# AT32A423xx_v2 register map
Vendor: Keil; Series: AT32A423; File version: 1.0
CPU: CM4 r0p1, little endian, no MPU, FPU, 4 interrupt priority bits
Registers are 32-bit, read-write, reset 0x0 unless marked. A register's access mark holds for its fields unless they carry their own. Offsets are from the block's base; [hi:lo] are bit positions; {n}, {i} and the like mark numbered series.

## EXINT
Base 0x40013C00
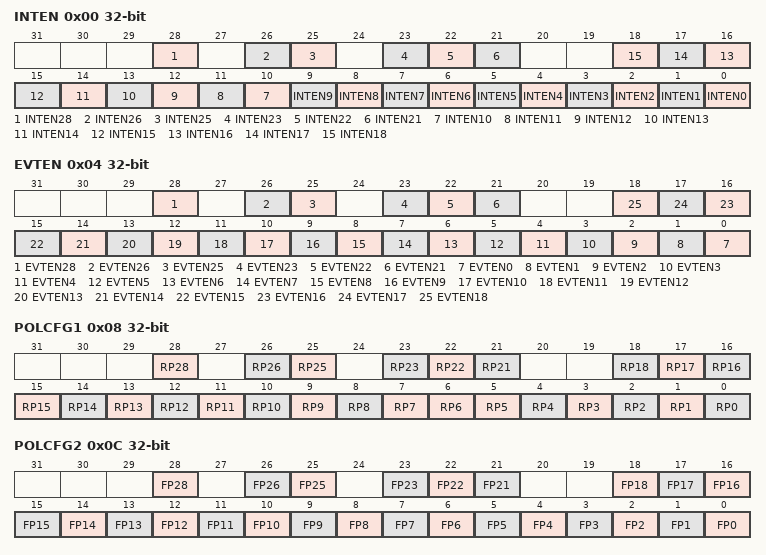
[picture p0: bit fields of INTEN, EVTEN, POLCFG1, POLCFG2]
0x00 INTEN — Interrupt enable register
  [28] INTEN28 — Interrupt enable or disable on line 28
  [26] INTEN26 — Interrupt enable or disable on line 26
  [25] INTEN25 — Interrupt enable or disable on line 25
  [23] INTEN23 — Interrupt enable or disable on line 23
  [22] INTEN22 — Interrupt enable or disable on line 22
  [21] INTEN21 — Interrupt enable or disable on line 21
  [n] INTEN{n} (n=0..18) — Interrupt enable or disable on line {n}
0x04 EVTEN — Event enable register
  [28] EVTEN28 — Event enable or disable on line 28
  [26] EVTEN26 — Event enable or disable on line 26
  [25] EVTEN25 — Event enable or disable on line 25
  [23] EVTEN23 — Event enable or disable on line 23
  [22] EVTEN22 — Event enable or disable on line 22
  [21] EVTEN21 — Event enable or disable on line 21
  [n] EVTEN{n} (n=0..18) — Event enable or disable on line {n}
0x08 POLCFG1 — Rising polarity configuration register
  [28] RP28 — Rising polarity configuration bit of line 28
  [26] RP26 — Rising polarity configuration bit of line 26
  [25] RP25 — Rising polarity configuration bit of line 25
  [23] RP23 — Rising polarity configuration bit of line 23
  [22] RP22 — Rising polarity configuration bit of line 22
  [21] RP21 — Rising polarity configuration bit of line 21
  [n] RP{n} (n=7..18) — Rising polarity configuration bit of line {n}
  [6] RP6 — Rising polarity configuration bit of linee 6
  [n] RP{n} (n=0..5) — Rising polarity configuration bit of line {n}
0x0C POLCFG2 — Falling polarity configuration register
  [28] FP28 — Falling polarity event configuration bit of line 28
  [26] FP26 — Falling polarity event configuration bit of line 26
  [25] FP25 — Falling polarity event configuration bit of line 25
  [23] FP23 — Falling polarity event configuration bit of line 23
  [22] FP22 — Falling polarity event configuration bit of line 22
  [21] FP21 — Falling polarity event configuration bit of line 21
  [n] FP{n} (n=0..18) — Falling polarity event configuration bit of line {n}
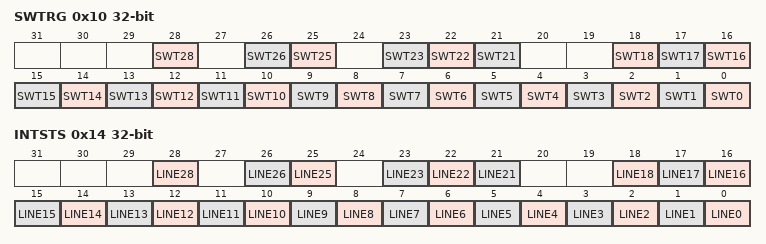
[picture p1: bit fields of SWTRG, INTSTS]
0x10 SWTRG — Software triggle register
  [28] SWT28 — Software triggle on line 28
  [26] SWT26 — Software triggle on line 26
  [25] SWT25 — Software triggle on line 255
  [23] SWT23 — Software triggle on line 233
  [22] SWT22 — Software triggle on line 22
  [21] SWT21 — Software triggle on line 21
  [n] SWT{n} (n=0..18) — Software triggle on line {n}
0x14 INTSTS — Interrupt status register
  [28] LINE28 — Line 28 state bit
  [26] LINE26 — Line 26 state bit
  [25] LINE25 — Line 25 state bit
  [23] LINE23 — Line 23 state bit
  [22] LINE22 — Line 22 state bit
  [21] LINE21 — Line 21 state bit
  [n] LINE{n} (n=0..18) — Line {n} state bit

## WDT — Watchdog
Base 0x40003000
0x00 CMD wo — Command register
  [15:0] CMD
0x04 DIV — Division register
  [2:0] DIV — Division divider
0x08 RLD reset 0xFFF — Reload register
  [11:0] RLD — Reload value
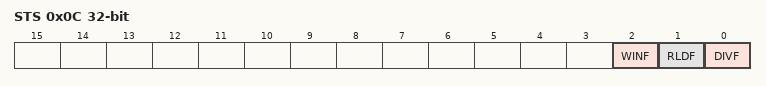
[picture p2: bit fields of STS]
0x0C STS ro — Status register
  [2] WINF — Window value update complete flag
  [1] RLDF — Reload value update complete flag
  [0] DIVF — Division value update complete flag
0x10 WIN reset 0xFFF — Window register
  [11:0] WIN — Window value

## WWDT — Window watchdog
Base 0x40002C00
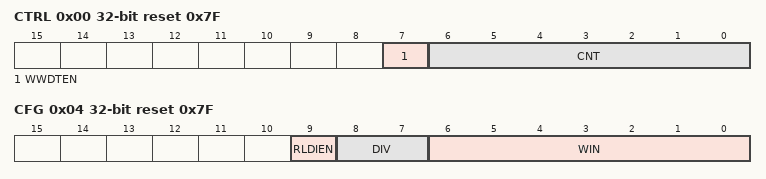
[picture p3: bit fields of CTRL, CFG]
0x00 CTRL reset 0x7F — Control register
  [7] WWDTEN — Window watchdog enable
  [6:0] CNT — Decrement counter
0x04 CFG reset 0x7F — Configuration register
  [9] RLDIEN — Reload counter interrupt
  [8:7] DIV — Clock division value
  [6:0] WIN — Window value
0x08 STS — Status register
  [0] RLDF — Reload counter interrupt flag

## TMR10 — General purpose timer
Base 0x40014400
Same registers: TMR13 0x40001C00, TMR11 0x40014800
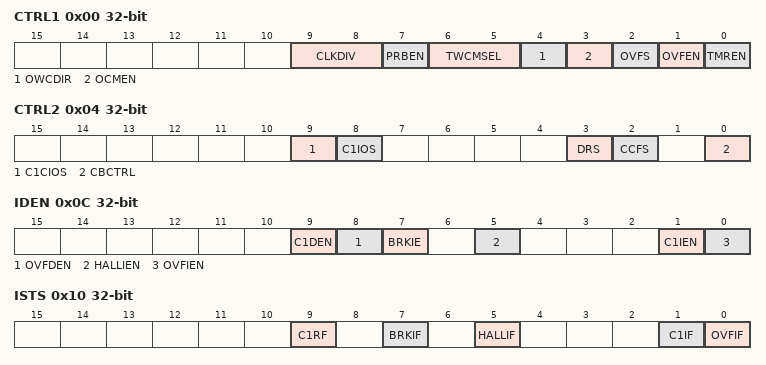
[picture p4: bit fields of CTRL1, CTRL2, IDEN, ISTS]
0x00 CTRL1 — Control register 1
  [9:8] CLKDIV — Clock divider
  [7] PRBEN — Period buffer enable
  [6:5] TWCMSEL — Two-way count mode selection
  [4] OWCDIR — One-way count direction
  [3] OCMEN — One cycle mode enable
  [2] OVFS — Overflow event source
  [1] OVFEN — Overflow event enable
  [0] TMREN — TMR enable
0x04 CTRL2 — Control register 2
  [9] C1CIOS — Channel 1 complementary idle output state
  [8] C1IOS — Channel 1 idle output state
  [3] DRS — DMA request source
  [2] CCFS — Channel control bit flash select
  [0] CBCTRL — Channel buffer control
0x0C IDEN — Interrupt/DMA enable register
  [9] C1DEN — Channel 1 DMA request enable
  [8] OVFDEN — Overflow DMA request enable
  [7] BRKIE — Brake interrupt enable
  [5] HALLIEN — HALL interrupt enable
  [1] C1IEN — Channel 1 interrupt enable
  [0] OVFIEN — Overflow interrupt enable
0x10 ISTS — Interrupt status register
  [9] C1RF — Channel 1 recapture flag
  [7] BRKIF — Brake interrupt flag
  [5] HALLIF — HALL interrupt flag
  [1] C1IF — Channel 1 interrupt flag
  [0] OVFIF — Overflow interrupt flag
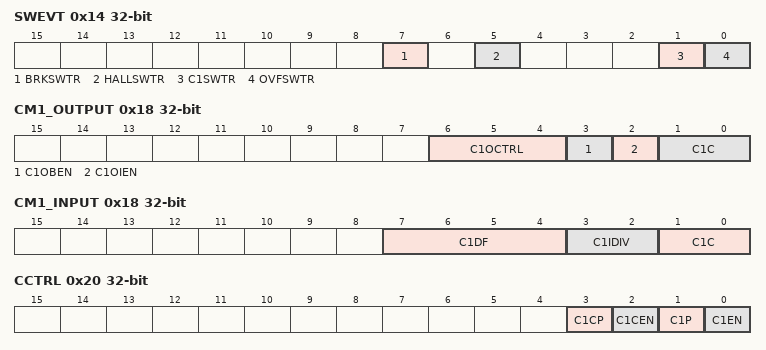
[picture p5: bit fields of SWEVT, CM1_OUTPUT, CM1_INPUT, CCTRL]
0x14 SWEVT — Software event register
  [7] BRKSWTR — Brake event triggered by software
  [5] HALLSWTR — HALL event triggered by software
  [1] C1SWTR — Channel 1 event triggered by software
  [0] OVFSWTR — Overflow event triggered by software
0x18 CM1_OUTPUT — Channel output mode register
  [6:4] C1OCTRL — Channel 1 output control
  [3] C1OBEN — Channel 1 output buffer enable
  [2] C1OIEN — Channel 1 output immediately enable
  [1:0] C1C — Channel 1 configure
0x18 CM1_INPUT (alternate view of CM1_OUTPUT) — Channel input mode register 1
  [7:4] C1DF — Channel 1 digital filter
  [3:2] C1IDIV — Channel 1 input divider
  [1:0] C1C — Channel 1 configure
0x20 CCTRL — Channel control register
  [3] C1CP — Channel 1 complementary polarity
  [2] C1CEN — Channel 1 complementary enable
  [1] C1P — Channel 1 Polarity
  [0] C1EN — Channel 1 enable
0x24 CVAL — Counter value
  [15:0] CVAL
0x28 DIV — Divider value
  [15:0] DIV
0x2C PR — Period value
  [15:0] PR
0x30 RPR — Repetition of period value
  [7:0] RPR
0x34 C1DT — Channel 1 data register
  [15:0] C1DT
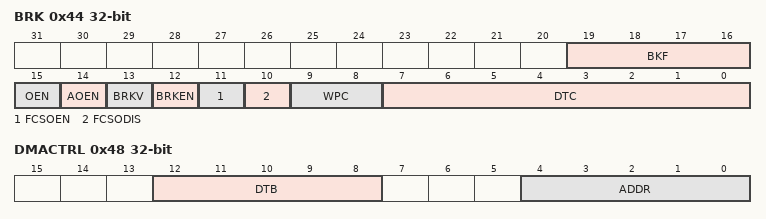
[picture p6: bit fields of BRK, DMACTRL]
0x44 BRK — Brake register
  [19:16] BKF — brake input filter
  [15] OEN — Output enable
  [14] AOEN — Automatic output enable
  [13] BRKV — Brake input validity
  [12] BRKEN — Brake enable
  [11] FCSOEN — Frozen channel status when holistic output enable
  [10] FCSODIS — Frozen channel status when holistic output disable
  [9:8] WPC — Write protected configuration
  [7:0] DTC — Dead-time configuration
0x48 DMACTRL — DMA control register
  [12:8] DTB — DMA transfer bytes
  [4:0] ADDR — DMA transfer address offset
0x4C DMADT — DMA data register
  [15:0] DMADT

## TMR14
Base 0x40002000
Registers as TMR10; these are added or differ:
0x50 RMP — TMR14 channel 1 input remap
  [7:6] TMR14_CH1_IRMP

## Notices in the file
Copyright (C) 2012-2014 ARM Limited. All rights reserved.
Purpose: System Viewer Description (SVD) Example (Schema Version 1.1)
This is a description of a none-existent and incomplete device
for demonstration purposes only.
Redistribution and use in source and binary forms, with or without
modification, are permitted provided that the following conditions are met:
- Redistributions of source code must retain the above copyright
notice, this list of conditions and the following disclaimer.
- Redistributions in binary form must reproduce the above copyright
notice, this list of conditions and the following disclaimer in the
documentation and/or other materials provided with the distribution.
- Neither the name of ARM nor the names of its contributors may be used
to endorse or promote products derived from this software without
specific prior written permission.
THIS SOFTWARE IS PROVIDED BY THE COPYRIGHT HOLDERS AND CONTRIBUTORS "AS IS"
AND ANY EXPRESS OR IMPLIED WARRANTIES, INCLUDING, BUT NOT LIMITED TO, THE
IMPLIED WARRANTIES OF MERCHANTABILITY AND FITNESS FOR A PARTICULAR PURPOSE
ARE DISCLAIMED. IN NO EVENT SHALL COPYRIGHT HOLDERS AND CONTRIBUTORS BE
LIABLE FOR ANY DIRECT, INDIRECT, INCIDENTAL, SPECIAL, EXEMPLARY, OR
CONSEQUENTIAL DAMAGES (INCLUDING, BUT NOT LIMITED TO, PROCUREMENT OF
SUBSTITUTE GOODS OR SERVICES; LOSS OF USE, DATA, OR PROFITS; OR BUSINESS
INTERRUPTION) HOWEVER CAUSED AND ON ANY THEORY OF LIABILITY, WHETHER IN
CONTRACT, STRICT LIABILITY, OR TORT (INCLUDING NEGLIGENCE OR OTHERWISE)
ARISING IN ANY WAY OUT OF THE USE OF THIS SOFTWARE, EVEN IF ADVISED OF THE
POSSIBILITY OF SUCH DAMAGE.
